# IMM100A register map
Vendor: Infineon; File version: 0.8.0 (Reference Manual v0.8.0)
CPU: CM0 r0p0, little endian, no MPU, no FPU, 2 interrupt priority bits
Registers are 32-bit, read-write, reset 0x0 unless marked. A register's access mark holds for its fields unless they carry their own. Offsets are from the block's base; [hi:lo] are bit positions; {n}, {i} and the like mark numbered series; 'fields as' and 'values as' point back to an identical list.

## CCU40_CC40 — Capture Compare Unit 4 - Unit 0
Base 0x48040100
Same registers: CCU40_CC41 0x48040200, CCU40_CC42 0x48040300, CCU40_CC43 0x48040400, CCU41_CC40 0x48044100, CCU41_CC41 0x48044200, CCU41_CC42 0x48044300, CCU41_CC43 0x48044400
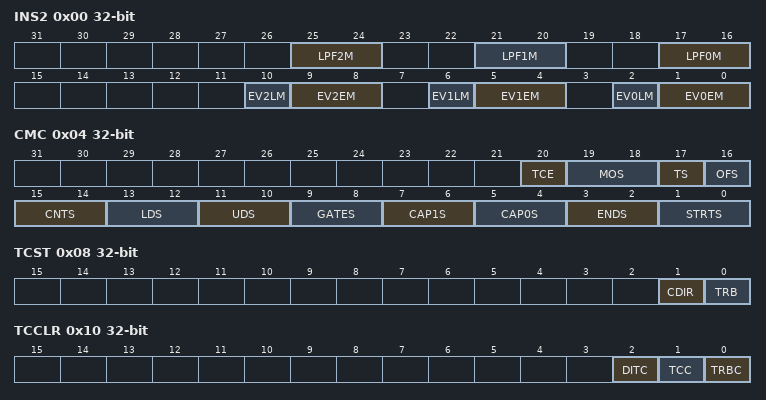
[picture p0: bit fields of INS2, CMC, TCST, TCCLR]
0x00 INS2 — Input Selector Configuration 2
  [25:24] LPF2M — Event 2 Low Pass Filter Configuration
    0=LPF is disabled; 1=3 clock cycles of fCCU4; 2=5 clock cycles of fCCU4; 3=7 clock cycles of fCCU4
  [21:20] LPF1M — Event 1 Low Pass Filter Configuration
    values as LPF2M
  [17:16] LPF0M — Event 0 Low Pass Filter Configuration
    values as LPF2M
  [10] EV2LM — Event 2 Level Selection
    0=Active on HIGH level; 1=Active on LOW level
  [9:8] EV2EM — Event 2 Edge Selection
    0=No action; 1=Signal active on rising edge; 2=Signal active on falling edge; 3=Signal active on both edges
  [6] EV1LM — Event 1 Level Selection
    0=Active on HIGH level; 1=Active on LOW level
  [5:4] EV1EM — Event 1 Edge Selection
    values as EV2EM
  [2] EV0LM — Event 0 Level Selection
    0=Active on HIGH level; 1=Active on LOW level
  [1:0] EV0EM — Event 0 Edge Selection
    values as EV2EM
0x04 CMC — Connection Matrix Control
  [20] TCE — Timer Concatenation Enable
    0=Timer concatenation is disabled; 1=Timer concatenation is enabled
  [19:18] MOS — External Modulation Functionality Selector
  [17] TS — Trap Function Selector
    0=Trap function disabled; 1=TRAP function connected to Event 2
  [16] OFS — Override Function Selector
    0=Override functionality disabled; 1=Status bit trigger override connected to Event 1; Status bit value override connected to Event 2
  [15:14] CNTS — External Count Selector
    0=External Count Function deactivated; 1=External Count Function triggered by Event 0; 2=External Count Function triggered by Event 1; 3=External Count Function triggered by Event 2
  [13:12] LDS — External Timer Load Functionality Selector
  [11:10] UDS — External Up/Down Functionality Selector
    0=External Up/Down Function deactivated; 1=External Up/Down Function triggered by Event 0; 2=External Up/Down Function triggered by Event 1; 3=External Up/Down Function triggered by Event 2
  [9:8] GATES — External Gate Functionality Selector
    0=External Gating Function deactivated; 1=External Gating Function triggered by Event 0; 2=External Gating Function triggered by Event 1; 3=External Gating Function triggered by Event 2
  [7:6] CAP1S — External Capture 1 Functionality Selector
    0=External Capture 1 Function deactivated; 1=External Capture 1 Function triggered by Event 0; 2=External Capture 1 Function triggered by Event 1; 3=External Capture 1 Function triggered by Event 2
  [5:4] CAP0S — External Capture 0 Functionality Selector
    0=External Capture 0 Function deactivated; 1=External Capture 0 Function triggered by Event 0; 2=External Capture 0 Function triggered by Event 1; 3=External Capture 0 Function triggered by Event 2
  [3:2] ENDS — External Stop Functionality Selector
    0=External Stop Function deactivated; 1=External Stop Function triggered by Event 0; 2=External Stop Function triggered by Event 1; 3=External Stop Function triggered by Event 2
  [1:0] STRTS — External Start Functionality Selector
    0=External Start Function deactivated; 1=External Start Function triggered by Event 0; 2=External Start Function triggered by Event 1; 3=External Start Function triggered by Event 2
0x08 TCST ro — Slice Timer Status
  [1] CDIR — Timer Counting Direction
    0=Timer is counting up; 1=Timer is counting down
  [0] TRB — Timer Run Bit
    0=Timer is stopped; 1=Timer is running
0x0C TCSET wo — Slice Timer Run Set
  [0] TRBS — Timer Run Bit set
0x10 TCCLR wo — Slice Timer Clear
  [2] DITC — Dither Counter Clear
  [1] TCC — Timer Clear
  [0] TRBC — Timer Run Bit Clear
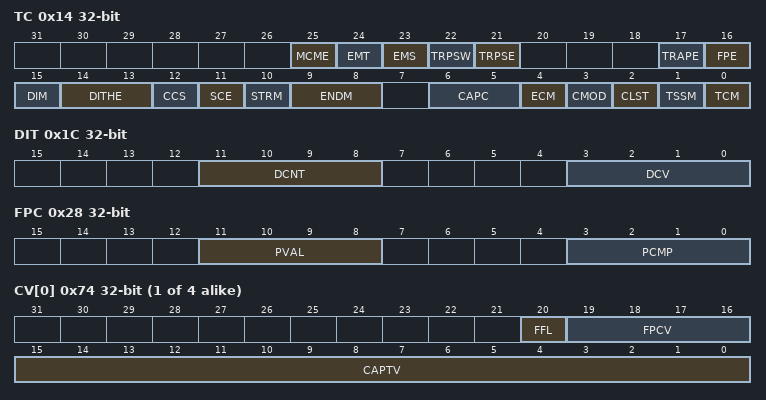
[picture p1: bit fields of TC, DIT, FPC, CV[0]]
0x14 TC access per field — Slice Timer Control
  [25] MCME rw — Multi Channel Mode Enable
    0=Multi Channel Mode is disabled; 1=Multi Channel Mode is enabled
  [24] EMT rw — External Modulation Type
    0=External Modulation functionality is clearing the CC4yST bit; 1=External Modulation functionality is gating the outputs
  [23] EMS rw — External Modulation Synchronization
    0=External Modulation functionality is not synchronized with the PWM signal; 1=External Modulation functionality is synchronized with the PWM signal
  [22] TRPSW rw — TRAP State Clear Control
    0=The slice exits the TRAP state automatically when the TRAP condition is not present; 1=The TRAP state can only be exited by a SW request
  [21] TRPSE rw — TRAP Synchronization Enable
    0=Exiting from TRAP state isn't synchronized with the PWM signal; 1=Exiting from TRAP state is synchronized with the PWM signal
  [17] TRAPE rw — TRAP enable
    0=TRAP functionality has no effect on the output; 1=TRAP functionality affects the output
  [16] FPE rw — Floating Prescaler enable
    0=Floating prescaler mode is disabled; 1=Floating prescaler mode is enabled
  [15] DIM rw — Dither input selector
    0=Slice is using its own dither unit; 1=Slice is connected to the dither unit of slice 0
  [14:13] DITHE rw — Dither Enable
    0=Dither is disabled; 1=Dither is applied to the Period; 2=Dither is applied to the Compare; 3=Dither is applied to the Period and Compare
  [12] CCS rw — Continuous Capture Enable
    0=The capture into a specific capture register is done with the rules linked with the full flags, described at ; 1=The capture into the capture registers is always done regardless of the full flag status (even if the register has not been read back)
  [11] SCE rw — Equal Capture Event enable
    0=Capture into CC4yC0VThis register contains the values associated with the Capture 0 field./CC4yC1VThis register contains the values associated with the Capture 1 field. registers control by CCycapt0 and capture into CC4yC3VThis register contains the values associated with the Capture 3 field./CC4yC2VThis register contains the values associated with the Capture 2 field. control by CCycapt1; 1=Capture into CC4yC0VThis register contains the values associated with the Capture 0 field./CC4yC1VThis register contains the values associated with the Capture 1 field. and CC4yC3VThis register contains the values associated with the Capture 3 field./CC4yC2VThis register contains the values associated with the Capture 2 field. control by CCycapt1
  [10] STRM rw — Extended Start Function Control
    0=Sets run bit only (default start); 1=Clears the timer and sets run bit (flush/start)
  [9:8] ENDM rw — Extended Stop Function Control
    0=Clears the timer run bit only (default stop); 1=Clears the timer only (flush); 2=Clears the timer and run bit (flush/stop)
  [6:5] CAPC rw — Clear on Capture Control
    0=Timer is never cleared on a capture event; 1=Timer is cleared on a capture event into capture registers 2 and 3. (When SCE = 1#, Timer is always cleared in a capture event); 2=Timer is cleared on a capture event into capture registers 0 and 1. (When SCE = 1#, Timer is always cleared in a capture event); 3=Timer is always cleared in a capture event
  [4] ECM rw — Extended Capture Mode
    0=Normal Capture Mode. Clear of the Full Flag of each capture register is done by accessing the registers individually only.; 1=Extended Capture Mode. Clear of the Full Flag of each capture register is done not only by accessing the individual registers but also by accessing the ECRD register. When reading the ECRD register, only the capture register register full flag pointed by the ECRD.VPTR is cleared.
  [3] CMOD ro — Capture Compare Mode
    0=Compare Mode; 1=Capture Mode
  [2] CLST rw — Shadow Transfer on Clear
  [1] TSSM rw — Timer Single Shot Mode
    0=Single shot mode is disabled; 1=Single shot mode is enabled
  [0] TCM rw — Timer Counting Mode
    0=Edge aligned mode; 1=Center aligned mode
0x18 PSL — Passive Level Config
  [0] PSL — Output Passive Level
    0=Passive Level is LOW; 1=Passive Level is HIGH
0x1C DIT ro — Dither Config
  [11:8] DCNT — Dither counter actual value
  [3:0] DCV — Dither compare Value
0x20 DITS — Dither Shadow Register
  [3:0] DCVS — Dither Shadow Compare Value
0x24 PSC — Prescaler Control
  [3:0] PSIV — Prescaler Initial Value
0x28 FPC access per field — Floating Prescaler Control
  [11:8] PVAL rw — Actual Prescaler Value
  [3:0] PCMP ro — Floating Prescaler Compare Value
0x2C FPCS — Floating Prescaler Shadow
  [3:0] PCMP — Floating Prescaler Shadow Compare Value
0x30 PR ro — Timer Period Value
  [15:0] PR — Period Register
0x34 PRS — Timer Shadow Period Value
  [15:0] PRS — Period Register
0x38 CR ro — Timer Compare Value
  [15:0] CR — Compare Register
0x3C CRS — Timer Shadow Compare Value
  [15:0] CRS — Compare Register
0x70 TIMER — Timer Value
  [15:0] TVAL
{0x74+4i} CV[{i}] (i=0..3) ro read-has-side-effects — Capture Register 0
  [20] FFL — Full Flag
    0=No new value was captured into the specific capture register; 1=A new value was captured into the specific register
  [19:16] FPCV — Prescaler Value
  [15:0] CAPTV — Capture Value
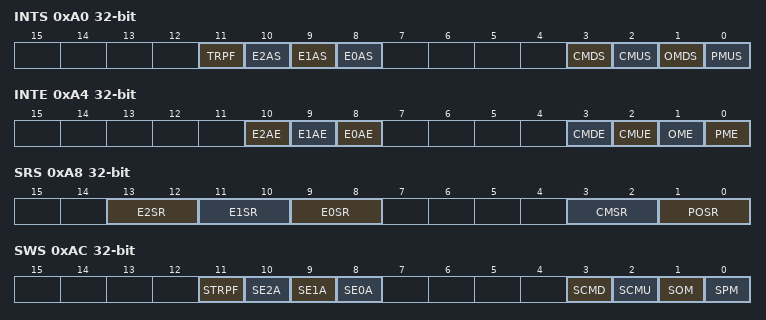
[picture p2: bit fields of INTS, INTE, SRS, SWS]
0xA0 INTS ro — Interrupt Status
  [11] TRPF — Trap Flag Status
  [10] E2AS — Event 2 Detection Status
    0=Event 2 not detected; 1=Event 2 detected
  [9] E1AS — Event 1 Detection Status
    0=Event 1 not detected; 1=Event 1 detected
  [8] E0AS — Event 0 Detection Status
    0=Event 0 not detected; 1=Event 0 detected
  [3] CMDS — Compare Match while Counting Down
    0=Compare match while counting down not detected; 1=Compare match while counting down detected
  [2] CMUS — Compare Match while Counting Up
    0=Compare match while counting up not detected; 1=Compare match while counting up detected
  [1] OMDS — One Match while Counting Down
    0=One match while counting down not detected; 1=One match while counting down detected
  [0] PMUS — Period Match while Counting Up
    0=Period match while counting up not detected; 1=Period match while counting up detected
0xA4 INTE — Interrupt Enable Control
  [10] E2AE — Event 2 interrupt enable
    0=Event 2 detection interrupt is disabled; 1=Event 2 detection interrupt is enabled
  [9] E1AE — Event 1 interrupt enable
    0=Event 1 detection interrupt is disabled; 1=Event 1 detection interrupt is enabled
  [8] E0AE — Event 0 interrupt enable
    0=Event 0 detection interrupt is disabled; 1=Event 0 detection interrupt is enabled
  [3] CMDE — Compare match while counting down enable
    0=Compare Match while counting down interrupt is disabled; 1=Compare Match while counting down interrupt is enabled
  [2] CMUE — Compare match while counting up enable
    0=Compare Match while counting up interrupt is disabled; 1=Compare Match while counting up interrupt is enabled
  [1] OME — One match while counting down enable
    0=One Match interrupt is disabled; 1=One Match interrupt is enabled
  [0] PME — Period match while counting up enable
    0=Period Match interrupt is disabled; 1=Period Match interrupt is enabled
0xA8 SRS — Service Request Selector
  [all] fields
    {v}=Forward to CC4ySR{v} (v=0..3)
  [13:12] E2SR — Event 2 Service request selector
  [11:10] E1SR — Event 1 Service request selector
  [9:8] E0SR — Event 0 Service request selector
  [3:2] CMSR — Compare match Service request selector
  [1:0] POSR — Period/One match Service request selector
0xAC SWS wo — Interrupt Status Set
  [11] STRPF — Trap Flag status set
  [10] SE2A — Event 2 detection set
  [9] SE1A — Event 1 detection set
  [8] SE0A — Event 0 detection set
  [3] SCMD — Compare match while counting down set
  [2] SCMU — Compare match while counting up set
  [1] SOM — One match while counting down set
  [0] SPM — Period match while counting up set
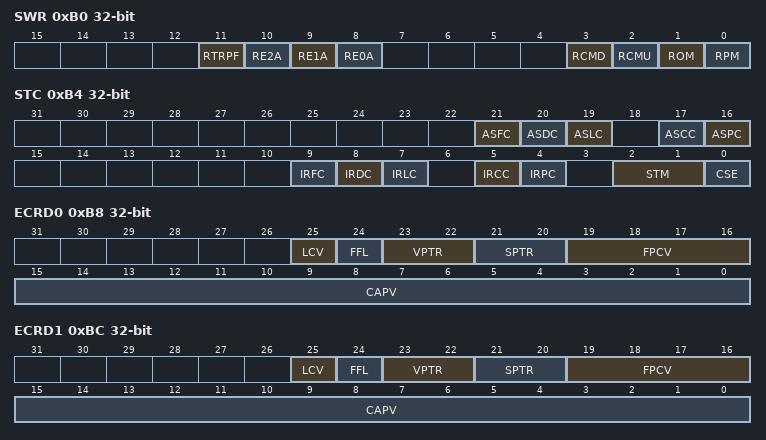
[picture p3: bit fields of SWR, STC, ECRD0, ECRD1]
0xB0 SWR wo — Interrupt Status Clear
  [11] RTRPF — Trap Flag status clear
  [10] RE2A — Event 2 detection clear
  [9] RE1A — Event 1 detection clear
  [8] RE0A — Event 0 detection clear
  [3] RCMD — Compare match while counting down clear
  [2] RCMU — Compare match while counting up clear
  [1] ROM — One match while counting down clear
  [0] RPM — Period match while counting up clear
0xB4 STC — Shadow transfer control
  [21] ASFC — Automatic Shadow transfer request when writing into Floating Prescaler Shadow register
    0=Writing into Floating Prescaler Shadow register does not automatically requests a shadow transfer; 1=Writing into Floating Prescaler Shadow register automatically requests a shadow transfer
  [20] ASDC — Automatic Shadow transfer request when writing into Dither Shadow register
    0=Writing into Dither Shadow register does not automatically requests a shadow transfer; 1=Writing into Dither Shadow register automatically requests a shadow transfer
  [19] ASLC — Automatic Shadow transfer request when writing into Passive Level register
    0=Writing into Passivel Level register does not automatically requests a shadow transfer; 1=Writing into Passive Level register automatically requests a shadow transfer
  [17] ASCC — Automatic Shadow transfer request when writing into Compare Shadow Register
    0=Writing into Compare Shadow register does not automatically requests a shadow transfer; 1=Writing into Compare Shadow register automatically requests a shadow transfer
  [16] ASPC — Automatic Shadow Transfer request when writing into Period Shadow Register
    0=Writing into Period Shadow register does not automatically requests a shadow transfer; 1=Writing into Period Shadow register will automatically requests a shadow transfer
  [9] IRFC — Immediate Write into Floating Prescaler Value Configuration
    0=Update of the floating prescaler value is done coherently with PWM cycle; 1=Update of the floating prescaler value happens immediately after a shadow transfer is request
  [8] IRDC — Immediate Write into Dither Value Configuration
    0=Update of the dither compare value is done coherently with PWM cycle; 1=Update of the dither compare value happens immediately after a shadow transfer is request
  [7] IRLC — Immediate Write into Passive Level Configuration
    0=Update of the pwm passive level is done coherently with PWM cycle; 1=Update of the pwm passive level value happens immediately after a shadow transfer is request
  [5] IRCC — Immediate Write into Compare Configuration
    0=Update of the compare value is done coherently with PWM cycle; 1=Update of the compare value happens immediately after a shadow transfer is request
  [4] IRPC — Immediate Write into Period Configuration
    0=Update of the period value is done coherently with PWM cycle; 1=Update of the period value happens immediately after a shadow transfer is request
  [2:1] STM — Shadow transfer mode
    0=Shadow transfer is done in Period Match and One match; 1=Shadow transfer is done only in Period Match; 2=Shadow transfer is done only in One Match
  [0] CSE — Cascaded shadow transfer enable
    0=Cascaded shadow transfer disabled; 1=Cascaded shadow transfer enabled
0xB8 ECRD0 ro read-has-side-effects — Extended Read Back 0
  [25] LCV — Lost Capture Value
    0=No capture was lost; 1=A capture was lost
  [24] FFL — Full Flag
    0=No new value was captured into this register; 1=A new value has been captured into this register
  [23:22] VPTR — Capture register pointer
    {v}=Capture register {v} (v=0..3)
  [21:20] SPTR — Slice pointer
    {v}=CC{v+40} (v=0..3)
  [19:16] FPCV — Prescaler Capture value
  [15:0] CAPV — Timer Capture Value
0xBC ECRD1 ro read-has-side-effects — Extended Read Back 1
  fields as ECRD0
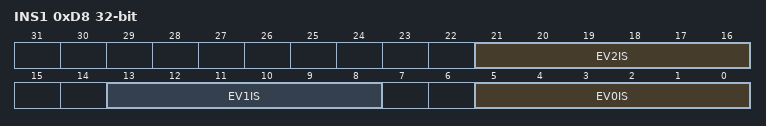
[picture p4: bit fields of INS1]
0xD8 INS1 — Input Selector Configuration 1
  [all] fields
    0=CCU4x.INyAA; 1=CCU4x.INyAB; 2=CCU4x.INyAC; 3=CCU4x.INyAD; 25=CCU4x.INyAZ; 26=CCU4x.INyBA; 27=CCU4x.INyBB; 47=CCU4x.INyBV
  [21:16] EV2IS — Event 2 signal selection
  [13:8] EV1IS — Event 1 signal selection
  [5:0] EV0IS — Event 0 signal selection
